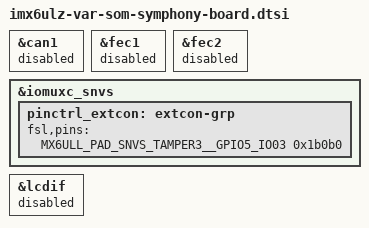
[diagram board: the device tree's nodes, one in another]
// SPDX-License-Identifier: GPL-2.0+
/*
 * Copyright (C) 2026 Variscite Ltd. - https://www.variscite.com
 */

#include "imx6ul-imx6ull-var-som-symphony-board.dtsi"

&can1 {
	status = "disabled";
};

&fec1 {
	status = "disabled";
};

&fec2 {
	status = "disabled";
};

&iomuxc_snvs {
	pinctrl_extcon: extcon-grp {
		fsl,pins = <
			MX6ULL_PAD_SNVS_TAMPER3__GPIO5_IO03	0x1b0b0
		>;
	};
};

&lcdif {
	status = "disabled";
};
